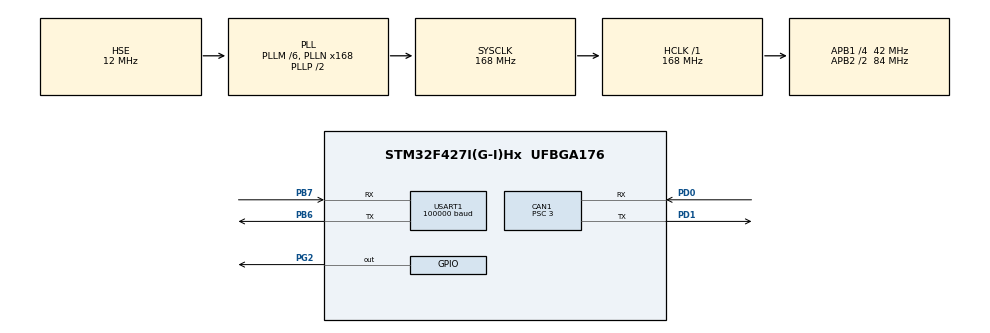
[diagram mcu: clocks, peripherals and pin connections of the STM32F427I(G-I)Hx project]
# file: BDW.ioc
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CAN1.BS1=CAN_BS1_9TQ
CAN1.BS2=CAN_BS2_4TQ
CAN1.CalculateBaudRate=1000000
CAN1.CalculateTimeBit=999.99
CAN1.CalculateTimeQuantum=71.42857142857143
CAN1.Prescaler=3
Dma.Request0=USART1_RX
Dma.USART1_RX.0.Direction=DMA_PERIPH_TO_MEMORY
Dma.USART1_RX.0.FIFOMode=DMA_FIFOMODE_DISABLE
Dma.USART1_RX.0.Instance=DMA2_Stream2
Dma.USART1_RX.0.MemDataAlignment=DMA_MDATAALIGN_BYTE
Dma.USART1_RX.0.MemInc=DMA_MINC_ENABLE
Dma.USART1_RX.0.Mode=DMA_CIRCULAR
Dma.USART1_RX.0.PeriphDataAlignment=DMA_PDATAALIGN_BYTE
Dma.USART1_RX.0.PeriphInc=DMA_PINC_DISABLE
Dma.USART1_RX.0.Priority=DMA_PRIORITY_LOW
Mcu.Family=STM32F4
Mcu.Name=STM32F427I(G-I)Hx
Mcu.Package=UFBGA176
NVIC.CAN1_RX0_IRQn=true\:0\:0\:false\:false\:true\:true\:true
NVIC.CAN1_TX_IRQn=true\:0\:0\:false\:false\:true\:true\:true
NVIC.DMA2_Stream2_IRQn=true\:0\:0\:false\:false\:true\:false\:true
NVIC.PriorityGroup=NVIC_PRIORITYGROUP_4
NVIC.USART1_IRQn=true\:0\:0\:false\:false\:true\:true\:true
PA13.Mode=Serial_Wire
PA13.Signal=SYS_JTMS-SWDIO
PA14.Mode=Serial_Wire
PA14.Signal=SYS_JTCK-SWCLK
PB6.Mode=Asynchronous
PB6.Signal=USART1_TX
PB7.Mode=Asynchronous
PB7.Signal=USART1_RX
PD0.Mode=CAN_Activate
PD0.Signal=CAN1_RX
PD1.Mode=CAN_Activate
PD1.Signal=CAN1_TX
PG2.Signal=GPIO_Output
PH0/OSC_IN.Mode=HSE-External-Oscillator
PH0/OSC_IN.Signal=RCC_OSC_IN
PH1/OSC_OUT.Mode=HSE-External-Oscillator
PH1/OSC_OUT.Signal=RCC_OSC_OUT
ProjectManager.HeapSize=0x200
ProjectManager.StackSize=0x400
ProjectManager.TargetToolchain=Makefile
RCC.48MHZClocksFreq_Value=84000000
RCC.AHBFreq_Value=168000000
RCC.APB1CLKDivider=RCC_HCLK_DIV4
RCC.APB1Freq_Value=42000000
RCC.APB1TimFreq_Value=84000000
RCC.APB2CLKDivider=RCC_HCLK_DIV2
RCC.APB2Freq_Value=84000000
RCC.APB2TimFreq_Value=168000000
RCC.CortexFreq_Value=168000000
RCC.HCLKFreq_Value=168000000
RCC.HSE_VALUE=12000000
RCC.HSI_VALUE=16000000
RCC.LSE_VALUE=32768
RCC.PLLM=6
RCC.PLLN=168
RCC.PLLSourceVirtual=RCC_PLLSOURCE_HSE
RCC.SYSCLKFreq_VALUE=168000000
RCC.SYSCLKSource=RCC_SYSCLKSOURCE_PLLCLK
RCC.VCOOutputFreq_Value=336000000
USART1.BaudRate=100000
USART1.VirtualMode=VM_ASYNC
board=custom

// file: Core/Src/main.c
/*
 * @Author: Yangyujian 2480383735@qq.com
 * @Date: 2023-11-27 14:35:34
 * @LastEditTime: 2023-11-28 08:50:28
 * @LastEditors: Yangyujian 2480383735@qq.com
 * @Description: 主程序
 * @FilePath: \BDW\Core\Src\main.c
 * 未经允许,请勿转载!!!
 */
/* USER CODE BEGIN Header */

/* USER CODE END Header */
#include "main.h"
#include "can.h"
#include "dma.h"
#include "usart.h"
#include "gpio.h"

/* USER CODE BEGIN PD */
extern rc_info_t rc;
char buf[200];
int count;

extern uint8_t MsgAvailable;
/* USER CODE END PD */

void SystemClock_Config(void);

int main(void)
{

  /* MCU Configuration--------------------------------------------------------*/

  /* Reset of all peripherals, Initializes the Flash interface and the Systick. */
  HAL_Init();

  /* Configure the system clock */
  SystemClock_Config();

  /* Initialize all configured peripherals */
  MX_GPIO_Init();
  MX_DMA_Init();
  MX_CAN1_Init();
  MX_USART1_UART_Init();
  /* USER CODE BEGIN 2 */

	HAL_CAN_Start(&hcan1);
  HAL_CAN_ActivateNotification(&hcan1, CAN_IT_RX_FIFO0_MSG_PENDING);    //开启CAN接收中断

	//HAL_UART_Init(&huart1);
	dbus_uart_init();

  /* USER CODE END 2 */

  /* Infinite loop */
  /* USER CODE BEGIN WHILE */

  while (1)
  {
    if(rc.sw4 > 1024)
    {

    }
    else{

    }
		HAL_Delay(100);
    /* USER CODE END WHILE */
  }
}

void SystemClock_Config(void)
{
  RCC_OscInitTypeDef RCC_OscInitStruct = {0};
  RCC_ClkInitTypeDef RCC_ClkInitStruct = {0};

  /** Configure the main internal regulator output voltage
  */
  __HAL_RCC_PWR_CLK_ENABLE();
  __HAL_PWR_VOLTAGESCALING_CONFIG(PWR_REGULATOR_VOLTAGE_SCALE1);
  /** Initializes the RCC Oscillators according to the specified parameters
  * in the RCC_OscInitTypeDef structure.
  */
  RCC_OscInitStruct.OscillatorType = RCC_OSCILLATORTYPE_HSE;
  RCC_OscInitStruct.HSEState = RCC_HSE_ON;
  RCC_OscInitStruct.PLL.PLLState = RCC_PLL_ON;
  RCC_OscInitStruct.PLL.PLLSource = RCC_PLLSOURCE_HSE;
  RCC_OscInitStruct.PLL.PLLM = 6;
  RCC_OscInitStruct.PLL.PLLN = 168;
  RCC_OscInitStruct.PLL.PLLP = RCC_PLLP_DIV2;
  RCC_OscInitStruct.PLL.PLLQ = 4;
  if (HAL_RCC_OscConfig(&RCC_OscInitStruct) != HAL_OK)
  {
    Error_Handler();
  }
  /** Initializes the CPU, AHB and APB buses clocks
  */
  RCC_ClkInitStruct.ClockType = RCC_CLOCKTYPE_HCLK|RCC_CLOCKTYPE_SYSCLK
                              |RCC_CLOCKTYPE_PCLK1|RCC_CLOCKTYPE_PCLK2;
  RCC_ClkInitStruct.SYSCLKSource = RCC_SYSCLKSOURCE_PLLCLK;
  RCC_ClkInitStruct.AHBCLKDivider = RCC_SYSCLK_DIV1;
  RCC_ClkInitStruct.APB1CLKDivider = RCC_HCLK_DIV4;
  RCC_ClkInitStruct.APB2CLKDivider = RCC_HCLK_DIV2;

  if (HAL_RCC_ClockConfig(&RCC_ClkInitStruct, FLASH_LATENCY_5) != HAL_OK)
  {
    Error_Handler();
  }
}

void Error_Handler(void)
{
  __disable_irq();
  while (1)
  {
  }
}

/************************ (C) COPYRIGHT STMicroelectronics *****END OF FILE****/
